AUTOSAR XML (schema 4-2-2)
package /ComponentTypes
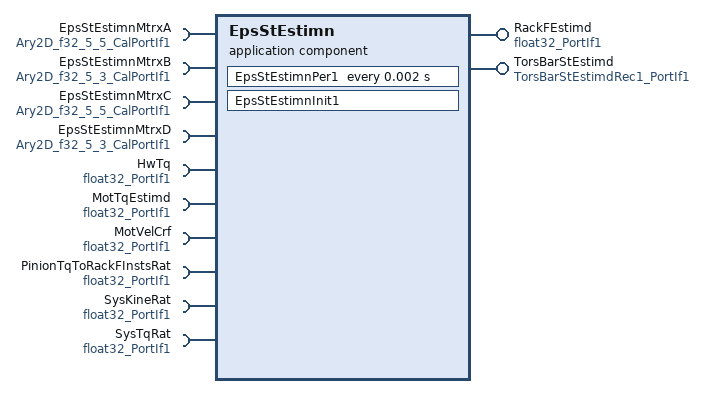
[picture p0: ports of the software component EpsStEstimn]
  application sw component type EpsStEstimn  # This component is used to estimate EPS system states from measurements of motor velocity, actual motor torque and handwheel torque.
    provide port RackFEstimd: nonqueued-sender-com-spec{data-element=Val, init-value=0}, provided-interface=float32_PortIf1  # Rack Force Estimated is a function of Pinion Torque to Rack Force Instantaneous Ratio
    provide port TorsBarStEstimd: nonqueued-sender-com-spec{data-element=Rec, init-value=fields=[MotVelEstimd:0, TorsBarTqEstimd:0, TorsBarRotatmEstimd:0, DrvrTqEstimd:0, RackTqEstimd:0]}, provided-interface=TorsBarStEstimdRec1_PortIf1  # Output of Torsion Bar State Estimated
    10 x require port:
      EpsStEstimnMtrxA: parameter-require-com-spec{init-value=[[1, 0, 0, 0, 0], [0, 1, 0, 0, 0], [0, 0, 1, 0, 0], [0, 0, 0, 1, 0], [0, 0, 0, 0, 1]], parameter=Ary2D}, required-interface=Ary2D_f32_5_5_CalPortIf1  # The State transition matrix of the state observer
      EpsStEstimnMtrxB: parameter-require-com-spec{init-value=5 x [0, 0, 0], parameter=Ary2D}, required-interface=Ary2D_f32_5_3_CalPortIf1  # EPS State Estimation Matrix B
      EpsStEstimnMtrxC: parameter-require-com-spec{init-value=[[1, 0, 0, 0, 0], [0, 1, 0, 0, 0], [0, 0, 1, 0, 0], [0, 0, 0, 1, 0], [0, 0, 0, 0, 1]], parameter=Ary2D}, required-interface=Ary2D_f32_5_5_CalPortIf1  # The output matrix of the state observer
      EpsStEstimnMtrxD: parameter-require-com-spec{init-value=5 x [0, 0, 0], parameter=Ary2D}, required-interface=Ary2D_f32_5_3_CalPortIf1
      HwTq: nonqueued-receiver-com-spec{data-element=Val, filter=data-filter-type=ALWAYS, init-value=0}, required-interface=float32_PortIf1  # Measured Handwheel Torque
      MotTqEstimd: nonqueued-receiver-com-spec{data-element=Val, filter=data-filter-type=ALWAYS, init-value=0}, required-interface=float32_PortIf1  # Motor Torque Estimated used to calculate State Estimator Input 1
      MotVelCrf: nonqueued-receiver-com-spec{data-element=Val, filter=data-filter-type=ALWAYS, init-value=0}, required-interface=float32_PortIf1  # Motor Velocity CRF used to calculate State Estimator Input 2
      PinionTqToRackFInstsRat: nonqueued-receiver-com-spec{data-element=Val, filter=data-filter-type=ALWAYS, init-value=60}, required-interface=float32_PortIf1  # Pinion Torque To Rack ForceInstantaneous Ratio used to calculate Rack Force Estimated
      SysKineRat: nonqueued-receiver-com-spec{data-element=Val, filter=data-filter-type=ALWAYS, init-value=10}, required-interface=float32_PortIf1  # System Kinematic Ratio used to calculate State Estimator Input 2
      SysTqRat: nonqueued-receiver-com-spec{data-element=Val, filter=data-filter-type=ALWAYS, init-value=10}, required-interface=float32_PortIf1  # System Torque Ratio used to calculate State Estimator Input 1
    behavior EpsStEstimn_InternalBehavior
      ar-typed-per-instance-memorys:
        data StEstimrStPrev: sw-calibration-access=READ-ONLY, type=Ary1D_f32_5  # PIM used to store previous value of State Estimator State
      init event EpsStEstimn_InitEvent: start-on-event=EpsStEstimnInit1
      timing event TMT_EpsStEstimnPer1: start-on-event=EpsStEstimnPer1, period=0.002
      port-api-options:
        enable-take-address=false, error-handling=NO-TRANSFORMER-ERROR-HANDLING, indirect-api=false, port=EpsStEstimnMtrxA
        enable-take-address=false, error-handling=NO-TRANSFORMER-ERROR-HANDLING, indirect-api=false, port=EpsStEstimnMtrxC
        enable-take-address=false, error-handling=NO-TRANSFORMER-ERROR-HANDLING, indirect-api=false, port=RackFEstimd
        enable-take-address=false, error-handling=NO-TRANSFORMER-ERROR-HANDLING, indirect-api=false, port=TorsBarStEstimd
      runnable EpsStEstimnInit1  # Initialization Runnable
      runnable EpsStEstimnPer1  # Periodic Runnable at 0.002 sec
        data-receive-point-by-arguments:
          6 x access:
            REC_HwTq_Val: accessed-variable=HwTq.Val
            REC_MotTqEstimd_Val: accessed-variable=MotTqEstimd.Val
            REC_MotVelCrf_Val: accessed-variable=MotVelCrf.Val
            REC_PinionTqToRackFInstsRat_Val: accessed-variable=PinionTqToRackFInstsRat.Val
            REC_SysKineRat_Val: accessed-variable=SysKineRat.Val
            REC_SysTqRat_Val: accessed-variable=SysTqRat.Val
        data-send-points:
          access SEND_RackFEstimd_Val: accessed-variable=RackFEstimd.Val
          access SEND_TorsBarStEstimd_Rec: accessed-variable=TorsBarStEstimd.Rec
  swc implementation EpsStEstimn_Implementation: behavior=EpsStEstimn_InternalBehavior
    code-descriptors:
      code Default: artifact-descriptors=autosar-engineering-object={short-label=Default, category=SWSRC}
